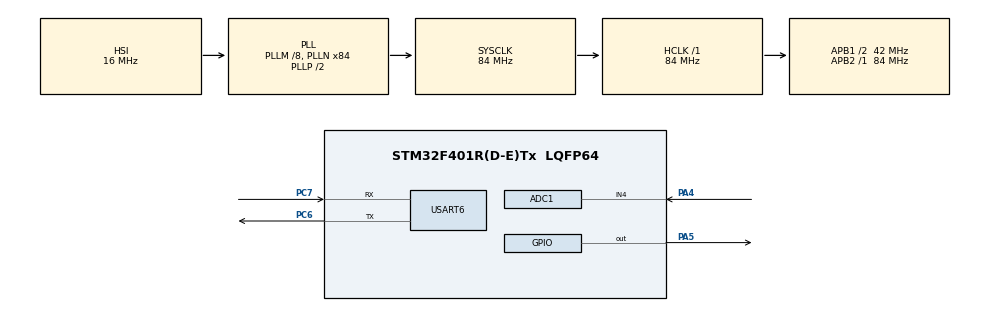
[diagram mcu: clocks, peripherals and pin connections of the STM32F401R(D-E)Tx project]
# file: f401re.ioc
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ADC1.Channel-0\#ChannelRegularConversion=ADC_CHANNEL_4
ADC1.NbrOfConversionFlag=1
ADC1.Rank-0\#ChannelRegularConversion=1
ADC1.SamplingTime-0\#ChannelRegularConversion=ADC_SAMPLETIME_3CYCLES
ADC1.master=1
FREERTOS.Tasks01=defaultTask,24,128,StartDefaultTask,Default,NULL,Dynamic,NULL,NULL
Mcu.Family=STM32F4
Mcu.Name=STM32F401R(D-E)Tx
Mcu.Package=LQFP64
NVIC.PriorityGroup=NVIC_PRIORITYGROUP_4
NVIC.TIM1_UP_TIM10_IRQn=true\:0\:0\:false\:false\:true\:false\:false\:true
NVIC.TimeBase=TIM1_UP_TIM10_IRQn
NVIC.TimeBaseIP=TIM1
PA13.Mode=Serial_Wire
PA13.Signal=SYS_JTMS-SWDIO
PA14.Mode=Serial_Wire
PA14.Signal=SYS_JTCK-SWCLK
PA4.Signal=ADCx_IN4
PA5.Signal=GPIO_Output
PC6.Mode=Asynchronous
PC6.Signal=USART6_TX
PC7.Mode=Asynchronous
PC7.Signal=USART6_RX
ProjectManager.HeapSize=0x200
ProjectManager.StackSize=0x400
ProjectManager.TargetToolchain=Makefile
RCC.48MHZClocksFreq_Value=42000000
RCC.AHBFreq_Value=84000000
RCC.APB1CLKDivider=RCC_HCLK_DIV2
RCC.APB1Freq_Value=42000000
RCC.APB1TimFreq_Value=84000000
RCC.APB2Freq_Value=84000000
RCC.APB2TimFreq_Value=84000000
RCC.CortexFreq_Value=84000000
RCC.HCLKFreq_Value=84000000
RCC.HSE_VALUE=25000000
RCC.HSI_VALUE=16000000
RCC.LSE_VALUE=32768
RCC.PLLM=8
RCC.PLLN=84
RCC.SYSCLKFreq_VALUE=84000000
RCC.SYSCLKSource=RCC_SYSCLKSOURCE_PLLCLK
RCC.VCOOutputFreq_Value=168000000
SH.ADCx_IN4.0=ADC1_IN4,IN4
USART6.VirtualMode=VM_ASYNC
VP_CRC_VS_CRC.Mode=CRC_Activate
VP_FREERTOS_VS_CMSIS_V2.Mode=CMSIS_V2
VP_SYS_VS_tim1.Mode=TIM1
board=custom

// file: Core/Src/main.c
/* USER CODE BEGIN Header */
/**
  ******************************************************************************
  * @file           : main.c
  * @brief          : Main program body
  ******************************************************************************
  * @attention
  *
  * <h2><center>&copy; Copyright (c) 2021 STMicroelectronics.
  * All rights reserved.</center></h2>
  *
  * This software component is licensed by ST under Ultimate Liberty license
  * SLA0044, the "License"; You may not use this file except in compliance with
  * the License. You may obtain a copy of the License at:
  *                             www.st.com/SLA0044
  *
  ******************************************************************************
  */
/* USER CODE END Header */
#include "main.h"
#include "cmsis_os.h"
#include "arm_math.h"

ADC_HandleTypeDef hadc1;

CRC_HandleTypeDef hcrc;

UART_HandleTypeDef huart6;

/* Definitions for defaultTask */
osThreadId_t defaultTaskHandle;
const osThreadAttr_t defaultTask_attributes = {
  .name = "defaultTask",
  .priority = (osPriority_t) osPriorityNormal,
  .stack_size = 128 * 4
};

void SystemClock_Config(void);
static void MX_GPIO_Init(void);
static void MX_ADC1_Init(void);
static void MX_CRC_Init(void);
static void MX_USART6_UART_Init(void);
void StartDefaultTask(void *argument);

int main(void)
{

  /* MCU Configuration--------------------------------------------------------*/

  /* Reset of all peripherals, Initializes the Flash interface and the Systick. */
  HAL_Init();

  /* Configure the system clock */
  SystemClock_Config();

  /* Initialize all configured peripherals */
  MX_GPIO_Init();
  MX_ADC1_Init();
  MX_CRC_Init();
  MX_USART6_UART_Init();

  /* Init scheduler */
  osKernelInitialize();

  /* Create the thread(s) */
  /* creation of defaultTask */
  defaultTaskHandle = osThreadNew(StartDefaultTask, NULL, &defaultTask_attributes);

  /* Start scheduler */
  osKernelStart();

  /* We should never get here as control is now taken by the scheduler */
  /* Infinite loop */
  while (1)
  {

  }
}

void SystemClock_Config(void)
{
  RCC_OscInitTypeDef RCC_OscInitStruct = {0};
  RCC_ClkInitTypeDef RCC_ClkInitStruct = {0};

  /** Configure the main internal regulator output voltage
  */
  __HAL_RCC_PWR_CLK_ENABLE();
  __HAL_PWR_VOLTAGESCALING_CONFIG(PWR_REGULATOR_VOLTAGE_SCALE2);
  /** Initializes the RCC Oscillators according to the specified parameters
  * in the RCC_OscInitTypeDef structure.
  */
  RCC_OscInitStruct.OscillatorType = RCC_OSCILLATORTYPE_HSI;
  RCC_OscInitStruct.HSIState = RCC_HSI_ON;
  RCC_OscInitStruct.HSICalibrationValue = RCC_HSICALIBRATION_DEFAULT;
  RCC_OscInitStruct.PLL.PLLState = RCC_PLL_ON;
  RCC_OscInitStruct.PLL.PLLSource = RCC_PLLSOURCE_HSI;
  RCC_OscInitStruct.PLL.PLLM = 8;
  RCC_OscInitStruct.PLL.PLLN = 84;
  RCC_OscInitStruct.PLL.PLLP = RCC_PLLP_DIV2;
  RCC_OscInitStruct.PLL.PLLQ = 4;
  if (HAL_RCC_OscConfig(&RCC_OscInitStruct) != HAL_OK)
  {
    Error_Handler();
  }
  /** Initializes the CPU, AHB and APB buses clocks
  */
  RCC_ClkInitStruct.ClockType = RCC_CLOCKTYPE_HCLK|RCC_CLOCKTYPE_SYSCLK
                              |RCC_CLOCKTYPE_PCLK1|RCC_CLOCKTYPE_PCLK2;
  RCC_ClkInitStruct.SYSCLKSource = RCC_SYSCLKSOURCE_PLLCLK;
  RCC_ClkInitStruct.AHBCLKDivider = RCC_SYSCLK_DIV1;
  RCC_ClkInitStruct.APB1CLKDivider = RCC_HCLK_DIV2;
  RCC_ClkInitStruct.APB2CLKDivider = RCC_HCLK_DIV1;

  if (HAL_RCC_ClockConfig(&RCC_ClkInitStruct, FLASH_LATENCY_2) != HAL_OK)
  {
    Error_Handler();
  }
}

static void MX_ADC1_Init(void)
{

  ADC_ChannelConfTypeDef sConfig = {0};

  /** Configure the global features of the ADC (Clock, Resolution, Data Alignment and number of conversion)
  */
  hadc1.Instance = ADC1;
  hadc1.Init.ClockPrescaler = ADC_CLOCK_SYNC_PCLK_DIV4;
  hadc1.Init.Resolution = ADC_RESOLUTION_12B;
  hadc1.Init.ScanConvMode = DISABLE;
  hadc1.Init.ContinuousConvMode = DISABLE;
  hadc1.Init.DiscontinuousConvMode = DISABLE;
  hadc1.Init.ExternalTrigConvEdge = ADC_EXTERNALTRIGCONVEDGE_NONE;
  hadc1.Init.ExternalTrigConv = ADC_SOFTWARE_START;
  hadc1.Init.DataAlign = ADC_DATAALIGN_RIGHT;
  hadc1.Init.NbrOfConversion = 1;
  hadc1.Init.DMAContinuousRequests = DISABLE;
  hadc1.Init.EOCSelection = ADC_EOC_SINGLE_CONV;
  if (HAL_ADC_Init(&hadc1) != HAL_OK)
  {
    Error_Handler();
  }
  /** Configure for the selected ADC regular channel its corresponding rank in the sequencer and its sample time.
  */
  sConfig.Channel = ADC_CHANNEL_4;
  sConfig.Rank = 1;
  sConfig.SamplingTime = ADC_SAMPLETIME_3CYCLES;
  if (HAL_ADC_ConfigChannel(&hadc1, &sConfig) != HAL_OK)
  {
    Error_Handler();
  }

}

static void MX_CRC_Init(void)
{

  hcrc.Instance = CRC;
  if (HAL_CRC_Init(&hcrc) != HAL_OK)
  {
    Error_Handler();
  }

}

static void MX_USART6_UART_Init(void)
{

  huart6.Instance = USART6;
  huart6.Init.BaudRate = 115200;
  huart6.Init.WordLength = UART_WORDLENGTH_8B;
  huart6.Init.StopBits = UART_STOPBITS_1;
  huart6.Init.Parity = UART_PARITY_NONE;
  huart6.Init.Mode = UART_MODE_TX_RX;
  huart6.Init.HwFlowCtl = UART_HWCONTROL_NONE;
  huart6.Init.OverSampling = UART_OVERSAMPLING_16;
  if (HAL_UART_Init(&huart6) != HAL_OK)
  {
    Error_Handler();
  }

}

static void MX_GPIO_Init(void)
{
  GPIO_InitTypeDef GPIO_InitStruct = {0};

  /* GPIO Ports Clock Enable */
  __HAL_RCC_GPIOA_CLK_ENABLE();
  __HAL_RCC_GPIOC_CLK_ENABLE();

  /*Configure GPIO pin Output Level */
  HAL_GPIO_WritePin(GPIOA, GPIO_PIN_5, GPIO_PIN_RESET);

  /*Configure GPIO pin : PA5 */
  GPIO_InitStruct.Pin = GPIO_PIN_5;
  GPIO_InitStruct.Mode = GPIO_MODE_OUTPUT_PP;
  GPIO_InitStruct.Pull = GPIO_NOPULL;
  GPIO_InitStruct.Speed = GPIO_SPEED_FREQ_LOW;
  HAL_GPIO_Init(GPIOA, &GPIO_InitStruct);

}

void StartDefaultTask(void *argument)
{
  /* USER CODE BEGIN 5 */
  /* Infinite loop */
  for(;;)
  {
    HAL_UART_Transmit(&huart6,"test\n",5,0xffff);
    osDelay(1);
  }
  /* USER CODE END 5 */
}

void HAL_TIM_PeriodElapsedCallback(TIM_HandleTypeDef *htim)
{
  if (htim->Instance == TIM1) {
    HAL_IncTick();
  }
}

void Error_Handler(void)
{
}

/************************ (C) COPYRIGHT STMicroelectronics *****END OF FILE****/
